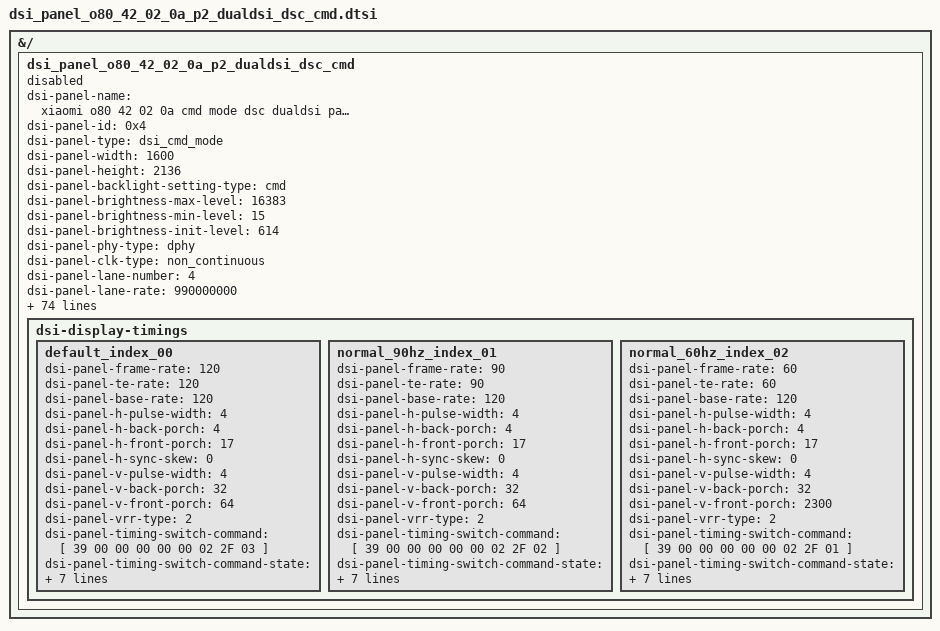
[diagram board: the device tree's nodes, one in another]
// SPDX-License-Identifier: GPL-2.0+
/*
 * DSI panel device tree for fpga testing
 *
 * (C) Copyright 2023 - 2024, X-Ring, Inc.
 */
&{/} {
	dsi_panel_o80_42_02_0a_p2_dualdsi_dsc_cmd: dsi_panel_o80_42_02_0a_p2_dualdsi_dsc_cmd {
		status = "disabled";
		dsi-panel-name = "xiaomi o80 42 02 0a cmd mode dsc dualdsi panel";
		dsi-panel-id = <0x4>;
		dsi-panel-type = "dsi_cmd_mode";
		dsi-panel-width = <1600>;
		dsi-panel-height = <2136>;
		dsi-panel-backlight-setting-type = "cmd";
		dsi-panel-brightness-max-level = <16383>;
		dsi-panel-brightness-min-level = <15>;
		dsi-panel-brightness-init-level = <614>;
		dsi-panel-phy-type = "dphy";
		dsi-panel-clk-type = "non_continuous";
		dsi-panel-lane-number = <4>;
		dsi-panel-lane-rate =  <990000000>;
		dsi-panel-pixel-clock = <20625000>;
		dsi-panel-phy-amplitude = <2>; // 225mv
		dsi-panel-phy-oa-setr = <0>;
		dsi-panel-phy-eqa = <0>;
		dsi-panel-phy-eqb = <0>;
		dsi-panel-bpp = <30>;
		dsi-panel-virtual-channel = <0>;
		//dsi-panel-bta-enable;
		//dsi-panel-eotp-enable;
		//dsi-panel-esd-check-enable;
		dsi-panel-hdr-enabled;
		dsi-panel-peak-brightness = <4200000>;
		dsi-panel-blackness-level = <3230>;
		dsi-panel-physical-width-dimension = <2950>;
		dsi-panel-physical-height-dimension = <1974>;
		dsi-panel-physical-type = "ltpo";
		dsi-panel-te-sel = /bits/ 8 <0x0>;
		dsi-panel-port-mask = /bits/ 8 <0x3>; // dual port
		dsi-panel-boot-up-profile = <1>; //profile_1
		dsi-panel-lowpower-ctrl = <0x9d>;
		dsi-panel-frame-power-mask = <0x6>;
		dsi-panel-frame-power-max-refresh-rate = <30>;
		dsi-panel-idle-policy = <0x0>;
		dsi-panel-vrr-enable;
		dsi-panel-dsc-compression-mode = "dsc";
		dsi-panel-dsc-version = <0x12>;
		dsi-panel-dsc-scr-version = <0x0>;
		dsi-panel-dsc-pic-height = <2136>;
		dsi-panel-dsc-pic-width = <1600>; // dual dsi is 3200/2
		dsi-panel-dsc-slice-height = <24>;
		dsi-panel-dsc-slice-width = <800>;
		dsi-panel-dsc-bpc = /bits/ 8 <10>;
		dsi-panel-dsc-bpp = /bits/ 8 <8>;
		dsi-panel-dsc-pps-table = [
			12 00 00 AB 30 80 08 58 06 40 00 18 03 20 03 20 02 00
			02 B2 00 20 02 9F 00 0B 00 0D 04 86 02 DC 18 00 10 F0
			07 10 20 00 06 0F 0F 33 0E 1C 2A 38 46 54 62 69 70 77
			79 7B 7D 7E 02 02 22 00 2A 40 2A BE 3A FC 3A FA 3A F8
			3B 38 3B 78 3B B6 4B B6 4B F4 4B F4 6C 34 84 74 00 00
			00 00 00 00 00 00 00 00 00 00 00 00 00 00 00 00 00 00
			00 00 00 00 00 00 00 00 00 00 00 00 00 00 00 00 00 00
			00 00
		];
		dsi-panel-reset-after-lp11;
		dsi-display-timings {
			default_index_00{
				#include "dsi_panel_o80_42_02_0a_p2_dualdsi_dsc_cmd_common.dtsi"
				dsi-panel-frame-rate = <120>;
				dsi-panel-te-rate = <120>;
				dsi-panel-base-rate = <120>;
				dsi-panel-h-pulse-width = <4>;
				dsi-panel-h-back-porch = <4>;
				dsi-panel-h-front-porch = <17>;
				dsi-panel-h-sync-skew = <0>;
				dsi-panel-v-pulse-width = <4>;
				dsi-panel-v-back-porch = <32>;
				dsi-panel-v-front-porch = <64>;
				dsi-panel-vrr-type = <2>;

				dsi-panel-timing-switch-command = [
					/* 120Hz */
					39 00 00 00 00 00 02 2F 03
				];
				dsi-panel-timing-switch-command-state = "dsi_hs_mode";

				dsi-panel-on-command = [
					#include "dsi_panel_o80_42_02_0a_p2_dualdsi_dsc_cmd_on_common.dtsi"
					/* 120Hz */
					39 00 00 00 00 00 02 2F 03
					39 00 00 00 00 00 02 A3 81
					39 00 00 00 14 00 02 11 00

					39 00 00 04 00 00 13 A3 81 04 37 04 37 02 04 B5 02 03 00 03 00 00 00 00 00 00
					39 00 00 04 00 00 02 6F 12
					39 00 00 04 00 00 0E A3 01 00 9D 00 00 AA 00 00 00 00 00 00 00
					39 00 00 04 00 00 02 6F 1F
					39 00 00 04 00 00 0E A3 02 00 C0 09 09 00 00 00 00 00 00 00 00
					39 00 00 04 00 00 02 6F 53
					39 00 00 04 00 00 0E A3 02 04 B5 02 03 00 0c 00 00 00 00 00 00
					39 00 00 04 00 00 02 6F 60
					39 00 00 04 00 00 0E A3 01 00 9D 00 00 AA 00 00 00 00 00 00 00
					39 00 00 04 00 00 02 6F 6D
					39 00 00 00 64 00 07 A3 02 00 C0 09 09 55
					39 00 00 00 00 00 02 29 00

					39 00 00 00 00 00 03 51 04 37
					39 00 00 00 00 00 03 51 1F FF
					/* normal brightness */
					39 00 00 00 10 00 03 51 00 00
					/* LVDET */
					39 00 00 00 00 00 06 F0 55 AA 52 08 01
					39 00 00 00 00 00 02 6F 02
					39 00 00 00 00 00 04 C7 07 77 20
				];
				dsi-panel-on-command-state = "dsi_hs_mode";

				dsi-panel-off-command = [
					39 00 00 00 46 00 02 28 00
					39 00 00 00 78 00 02 10 00
				];
				dsi-panel-off-command-state = "dsi_hs_mode";

			};
			normal_90hz_index_01{
				#include "dsi_panel_o80_42_02_0a_p2_dualdsi_dsc_cmd_common.dtsi"
				dsi-panel-frame-rate = <90>;
				dsi-panel-te-rate = <90>;
				dsi-panel-base-rate = <120>;
				dsi-panel-h-pulse-width = <4>;
				dsi-panel-h-back-porch = <4>;
				dsi-panel-h-front-porch = <17>;
				dsi-panel-h-sync-skew = <0>;
				dsi-panel-v-pulse-width = <4>;
				dsi-panel-v-back-porch = <32>;
				dsi-panel-v-front-porch = <64>;
				dsi-panel-vrr-type = <2>;

				dsi-panel-timing-switch-command = [
					/* 90Hz */
					39 00 00 00 00 00 02 2F 02
				];
				dsi-panel-timing-switch-command-state = "dsi_hs_mode";

				dsi-panel-on-command = [
					#include "dsi_panel_o80_42_02_0a_p2_dualdsi_dsc_cmd_on_common.dtsi"
					/* 90Hz */
					39 00 00 00 00 00 02 2F 02
					39 00 00 00 00 00 02 A3 81
					39 00 00 00 14 00 02 11 00

					39 00 00 04 00 00 13 A3 81 04 37 04 37 02 04 B5 02 03 00 03 00 00 00 00 00 00
					39 00 00 04 00 00 02 6F 12
					39 00 00 04 00 00 0E A3 01 00 9D 00 00 AA 00 00 00 00 00 00 00
					39 00 00 04 00 00 02 6F 1F
					39 00 00 04 00 00 0E A3 02 00 C0 09 09 00 00 00 00 00 00 00 00
					39 00 00 04 00 00 02 6F 53
					39 00 00 04 00 00 0E A3 02 04 B5 02 03 00 0c 00 00 00 00 00 00
					39 00 00 04 00 00 02 6F 60
					39 00 00 04 00 00 0E A3 01 00 9D 00 00 AA 00 00 00 00 00 00 00
					39 00 00 04 00 00 02 6F 6D
					39 00 00 00 64 00 07 A3 02 00 C0 09 09 55
					39 00 00 00 00 00 02 29 00
					39 00 00 00 00 00 03 51 04 37
					39 00 00 00 00 00 03 51 1F FF
					/* normal brightness */
					39 00 00 00 10 00 03 51 00 00
					/* LVDET */
					39 00 00 00 00 00 06 F0 55 AA 52 08 01
					39 00 00 00 00 00 02 6F 02
					39 00 00 00 00 00 04 C7 07 77 20
				];
				dsi-panel-on-command-state = "dsi_hs_mode";

				dsi-panel-off-command = [
					39 00 00 00 46 00 02 28 00
					39 00 00 00 78 00 02 10 00
				];
				dsi-panel-off-command-state = "dsi_hs_mode";
			};
			normal_60hz_index_02{
				#include "dsi_panel_o80_42_02_0a_p2_dualdsi_dsc_cmd_common.dtsi"
				dsi-panel-frame-rate = <60>;
				dsi-panel-te-rate = <60>;
				dsi-panel-base-rate = <120>;
				dsi-panel-h-pulse-width = <4>;
				dsi-panel-h-back-porch = <4>;
				dsi-panel-h-front-porch = <17>;
				dsi-panel-h-sync-skew = <0>;
				dsi-panel-v-pulse-width = <4>;
				dsi-panel-v-back-porch = <32>;
				dsi-panel-v-front-porch = <2300>;
				dsi-panel-vrr-type = <2>;

				dsi-panel-timing-switch-command = [
					/* 60Hz */
					39 00 00 00 00 00 02 2F 01
				];
				dsi-panel-timing-switch-command-state = "dsi_hs_mode";

				dsi-panel-on-command = [
					#include "dsi_panel_o80_42_02_0a_p2_dualdsi_dsc_cmd_on_common.dtsi"
					/* 60Hz */
					39 00 00 00 00 00 02 2F 01
					39 00 00 00 00 00 02 A3 81
					39 00 00 00 14 00 02 11 00

					39 00 00 04 00 00 13 A3 81 04 37 04 37 02 04 B5 02 03 00 03 00 00 00 00 00 00
					39 00 00 04 00 00 02 6F 12
					39 00 00 04 00 00 0E A3 01 00 9D 00 00 AA 00 00 00 00 00 00 00
					39 00 00 04 00 00 02 6F 1F
					39 00 00 04 00 00 0E A3 02 00 C0 09 09 00 00 00 00 00 00 00 00
					39 00 00 04 00 00 02 6F 53
					39 00 00 04 00 00 0E A3 02 04 B5 02 03 00 0c 00 00 00 00 00 00
					39 00 00 04 00 00 02 6F 60
					39 00 00 04 00 00 0E A3 01 00 9D 00 00 AA 00 00 00 00 00 00 00
					39 00 00 04 00 00 02 6F 6D
					39 00 00 00 64 00 07 A3 02 00 C0 09 09 55
					39 00 00 00 00 00 02 29 00
					39 00 00 00 00 00 03 51 04 37
					39 00 00 00 00 00 03 51 1F FF
					/* normal brightness */
					39 00 00 00 10 00 03 51 00 00
					/* LVDET */
					39 00 00 00 00 00 06 F0 55 AA 52 08 01
					39 00 00 00 00 00 02 6F 02
					39 00 00 00 00 00 04 C7 07 77 20
				];
				dsi-panel-on-command-state = "dsi_hs_mode";

				dsi-panel-off-command = [
					39 00 00 00 46 00 02 28 00
					39 00 00 00 78 00 02 10 00
				];
				dsi-panel-off-command-state = "dsi_hs_mode";
			};
		};
	};
};

&dsi_panel_o80_42_02_0a_p2_dualdsi_dsc_cmd {
	mi,panel-id = <0x007F3830 0x0042020B>;

	dsi-panel-esd-check-enable;
	dsi-panel-esd-mode = "err_int";
	dsi-panel-esd-err-irq-gpio-0 = <&dw_gpio0 11 0x2004>; // 11
	dsi-panel-erd-err-irq-gpio-0-flag = <0x2004>;
	dsi-panel-esd-err-irq-gpio-1 = <&dw_gpio2 3 0x2004>; // 67
	dsi-panel-esd-err-irq-gpio-1-flag = <0x2004>;

	dsi-panel-te-gpio = <&dw_gpio4 28 0>;  // 141

	/* enable round-corner */
	mi,ddic-round-corner-enabled;
        /* 0:default 1:port0 2:port1 3:dual port*/
	mi,ddic-round-corner-port-mode = <3>;
	mi,dsi-panel-fac-brightness-max-level = <8191>;
	mi,max-brightness-normal = <8191>;
	mi,dsi-panel-wp-read-command = [06 01 00 01 00 00 01 DD];
	mi,dsi-panel-wp-read-command-state = "dsi_hs_mode";
	mi,dsi-panel-wp-read-pre-tx-command = [39 00 00 00 00 00 06 F0 55 AA 52 08 00];
	mi,dsi-panel-wp-read-pre-tx-command-state = "dsi_hs_mode";
	mi,dsi-panel-wp-read-length = <3>;

	mi,panel-build-id-read-needed;
	mi,panel-build-id-read-length = <1>;
 	mi,dsi-panel-build-id-read-command = [06 01 00 01 00 00 01 DA];
 	mi,dsi-panel-build-id-read-command-state = "dsi_hs_mode";
	dsi-panel-read-build-id-length = <1>;
	dsi-panel-read-build-id-command = [06 01 00 01 00 00 01 DA];
	dsi-panel-read-build-id-command-state = "dsi_hs_mode";

	mi,panel-flatmode-status-check-enabled;
	mi,dsi-panel-flatmode-status-command = [06 01 00 01 00 00 01 5F];
	mi,dsi-panel-flatmode-status-command-state = "dsi_hs_mode";
	mi,dsi-panel-flatmode-status-read-length = <1>;
	mi,dsi-panel-flatmode-on-status-value = <0x00>;
};
